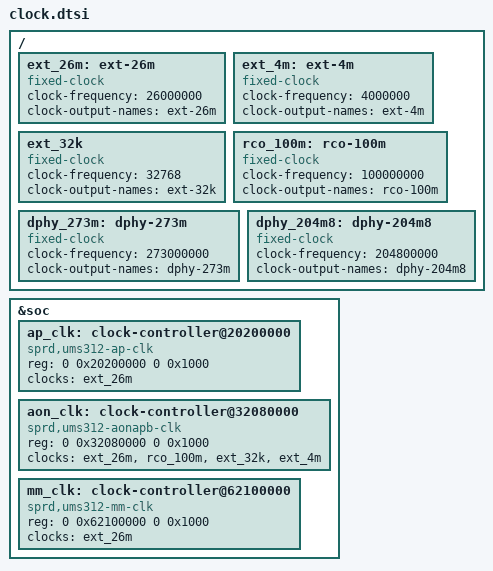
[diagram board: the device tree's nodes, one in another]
// SPDX-License-Identifier: GPL-2.0-only
/*
 * Unisoc UMS512 Clock DTS file
 *
 * Copyright (C) 2022, Unisoc Inc.
 */

&soc {
	ap_clk: clock-controller@20200000 {
		compatible = "sprd,ums312-ap-clk";
		reg = <0 0x20200000 0 0x1000>;
		clocks = <&ext_26m>;
		clock-names = "ext-26m";
		#clock-cells = <1>;
	};

	aon_clk: clock-controller@32080000 {
		compatible = "sprd,ums312-aonapb-clk";
		reg = <0 0x32080000 0 0x1000>;
		clocks = <&ext_26m>, <&rco_100m>, <&ext_32k>,
			 <&ext_4m>;
		clock-names = "ext-26m", "rco-100m", "ext-32k",
				  "ext-4m";
		#clock-cells = <1>;
	};

	mm_clk: clock-controller@62100000 {
		compatible = "sprd,ums312-mm-clk";
		reg = <0 0x62100000 0 0x1000>;
		clocks = <&ext_26m>;
		clock-names = "ext-26m";
		#clock-cells = <1>;
	};
};

/ {
	ext_26m: ext-26m {
		compatible = "fixed-clock";
		#clock-cells = <0>;
		clock-frequency = <26000000>;
		clock-output-names = "ext-26m";
	};

	ext_4m: ext-4m {
		compatible = "fixed-clock";
		#clock-cells = <0>;
		clock-frequency = <4000000>;
		clock-output-names = "ext-4m";
	};

	ext_32k: ext_32k {
		compatible = "fixed-clock";
		#clock-cells = <0>;
		clock-frequency = <32768>;
		clock-output-names = "ext-32k";
	};

	rco_100m: rco-100m {
		compatible = "fixed-clock";
		#clock-cells = <0>;
		clock-frequency = <100000000>;
		clock-output-names = "rco-100m";
	};

	dphy_273m: dphy-273m {
		compatible = "fixed-clock";
		#clock-cells = <0>;
		clock-frequency = <273000000>;
		clock-output-names = "dphy-273m";
	};

	dphy_204m8: dphy-204m8 {
		compatible = "fixed-clock";
		#clock-cells = <0>;
		clock-frequency = <204800000>;
		clock-output-names = "dphy-204m8";
	};
};
